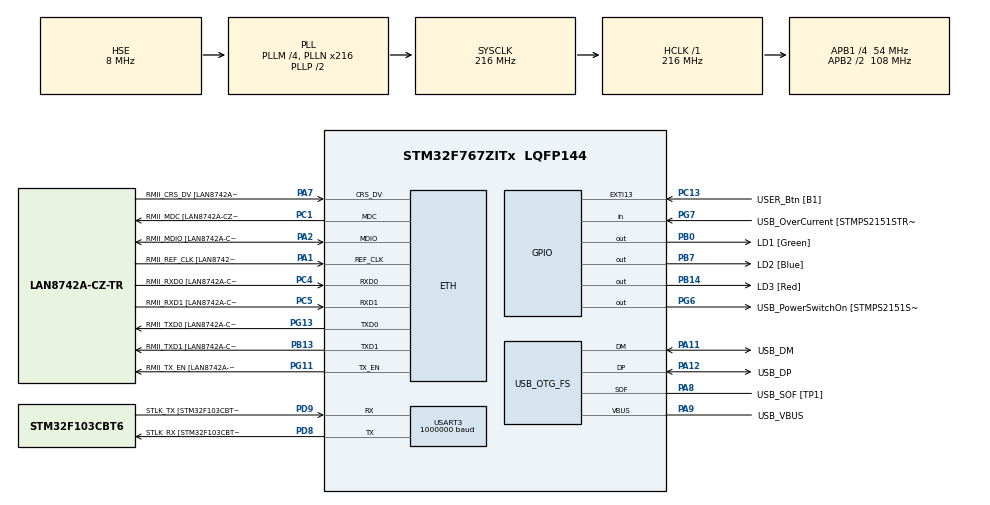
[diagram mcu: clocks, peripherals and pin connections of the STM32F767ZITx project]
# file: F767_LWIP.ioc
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Mcu.Family=STM32F7
NVIC.USART3_IRQn=true\:0\:0\:false\:false\:true\:true\:true
Dma.USART3_RX.0.PeriphInc=DMA_PINC_DISABLE
RCC.CortexFreq_Value=216000000
PG6.Signal=GPIO_Output
Dma.USART3_TX.1.MemInc=DMA_MINC_ENABLE
PB14.GPIO_Label=LD3 [Red]
PG6.GPIO_Label=USB_PowerSwitchOn [STMPS2151STR_EN]
PA14.GPIO_Label=TCK
RCC.SYSCLKSourceVirtual=RCC_SYSCLKSOURCE_PLLCLK
Dma.USART3_TX.1.PeriphDataAlignment=DMA_PDATAALIGN_BYTE
PA11.Mode=Device_Only
PB0.GPIO_Label=LD1 [Green]
PC14/OSC32_IN.Mode=LSE-External-Oscillator
Dma.USART3_TX.1.Instance=DMA1_Stream3
PC5.Mode=RMII
PC13.GPIO_Label=USER_Btn [B1]
PB13.GPIO_Label=RMII_TXD1 [LAN8742A-CZ-TR_TXD1]
PB13.Signal=ETH_TXD1
PG13.Signal=ETH_TXD0
PD9.Mode=Asynchronous
PG11.Signal=ETH_TX_EN
RCC.SYSCLKSource=RCC_SYSCLKSOURCE_PLLCLK
ProjectManager.StackSize=0x1000
USART3.VirtualMode-Asynchronous=VM_ASYNC
PA12.Signal=USB_OTG_FS_DP
USART3.BaudRate=1000000
ETH.PHY_Value=0
PH0/OSC_IN.Mode=HSE-External-Clock-Source
RCC.HCLKFreq_Value=216000000
RCC.APB2TimFreq_Value=216000000
PH1/OSC_OUT.Signal=RCC_OSC_OUT
PD8.Signal=USART3_TX
RCC.AHBFreq_Value=216000000
RCC.HSE_VALUE=8000000
LWIP.LWIP_HAVE_LOOPIF=1
Dma.USART3_RX.0.MemDataAlignment=DMA_MDATAALIGN_BYTE
Dma.USART3_TX.1.Mode=DMA_NORMAL
RCC.PLLMUL=RCC_PLL_MUL9
PC4.GPIO_Label=RMII_RXD0 [LAN8742A-CZ-TR_RXD0]
PA14.Mode=Serial_Wire
PA10.GPIO_Label=USB_ID
Dma.USART3_RX.0.PeriphDataAlignment=DMA_PDATAALIGN_BYTE
PB7.Signal=GPIO_Output
Dma.USART3_RX.0.FIFOMode=DMA_FIFOMODE_DISABLE
PA8.Signal=USB_OTG_FS_SOF
PG13.Mode=RMII
ETH.PHY_Name=LAN8742A_PHY_ADDRESS
TIM4.Period=999
PH1/OSC_OUT.Mode=HSE-External-Clock-Source
Dma.USART3_TX.1.FIFOMode=DMA_FIFOMODE_DISABLE
Dma.USART3_TX.1.Priority=DMA_PRIORITY_MEDIUM
PB7.GPIO_Label=LD2 [Blue]
Dma.USART3_RX.0.Direction=DMA_PERIPH_TO_MEMORY
Mcu.Package=LQFP144
PC14/OSC32_IN.Signal=RCC_OSC32_IN
PA2.GPIO_Label=RMII_MDIO [LAN8742A-CZ-TR_MDIO]
LWIP.LWIP_NETIF_LOOPBACK=0
PA10.Signal=USB_OTG_FS_ID
USB_OTG_FS.VirtualMode=Device_Only
Dma.USART3_RX.0.MemInc=DMA_MINC_ENABLE
RCC.APB2CLKDivider=RCC_HCLK_DIV2
Dma.Request1=USART3_TX
RCC.APB1TimFreq_Value=108000000
PG11.GPIO_Label=RMII_TX_EN [LAN8742A-CZ-TR_TXEN]
PC5.Signal=ETH_RXD1
PB13.Mode=RMII
Dma.USART3_TX.1.PeriphInc=DMA_PINC_DISABLE
Dma.Request0=USART3_RX
PC4.Mode=RMII
PB3.GPIO_Label=SWO
Dma.USART3_RX.0.Instance=DMA1_Stream1
Dma.USART3_TX.1.MemDataAlignment=DMA_MDATAALIGN_BYTE
PA7.Mode=RMII
PG7.Signal=GPIO_Input
PD9.GPIO_Label=STLK_TX [STM32F103CBT6_PA2]
PC13.Signal=GPXTI13
PA9.GPIO_Label=USB_VBUS
PC4.Signal=ETH_RXD0
LWIP.LWIP_IPV6=0
PA11.GPIO_Label=USB_DM
PD9.Signal=USART3_RX
NVIC.DMA1_Stream1_IRQn=true\:0\:0\:false\:false\:true\:false\:true
RCC.APB1CLKDivider=RCC_HCLK_DIV4
PG13.GPIO_Label=RMII_TXD0 [LAN8742A-CZ-TR_TXD0]
ETH.PhyAddress=0
PA12.GPIO_Label=USB_DP
Dma.USART3_RX.0.Mode=DMA_CIRCULAR
VP_LWIP_VS_Enabled.Mode=Enabled
PD8.GPIO_Label=STLK_RX [STM32F103CBT6_PA3]
PA13.Signal=SYS_JTMS-SWDIO
PA9.Mode=Activate_VBUS
PA8.GPIO_Label=USB_SOF [TP1]
LWIP.LWIP_NETIF_EXT_STATUS_CALLBACK=0
ProjectManager.TargetToolchain=MDK-ARM V5.27
LWIP.LWIP_NETIF_LINK_CALLBACK=0
PA9.Signal=USB_OTG_FS_VBUS
RCC.USBFreq_Value=48000000
TIM4.Prescaler=215
PD8.Mode=Asynchronous
PA1.Signal=ETH_REF_CLK
PB14.Signal=GPIO_Output
board=NUCLEO-F767ZI
RCC.VCOOutputFreq_Value=432000000
PH0/OSC_IN.Signal=RCC_OSC_IN
RCC.APB2Freq_Value=108000000
PA1.Mode=RMII
RCC.PRESCALERUSB=RCC_USBCLKSOURCE_PLL_DIV1_5
PG7.GPIO_Label=USB_OverCurrent [STMPS2151STR_FAULT]
PA1.GPIO_Label=RMII_REF_CLK [LAN8742A-CZ-TR_REFCLK0]
PC1.GPIO_Label=RMII_MDC [LAN8742A-CZ-TR_MDC]
PA13.Mode=Serial_Wire
Mcu.Name=STM32F767ZITx
PA2.Signal=ETH_MDIO
PA13.GPIO_Label=TMS
RCC.48MHZClocksFreq_Value=24000000
PB3.Signal=SYS_JTDO-SWO
RCC.SYSCLKFreq_VALUE=216000000
Dma.USART3_RX.0.Priority=DMA_PRIORITY_HIGH
ETH.MediaInterface=ETH_MEDIA_INTERFACE_RMII
PA7.GPIO_Label=RMII_CRS_DV [LAN8742A-CZ-TR_CRS_DV]
LWIP.LWIP_NETIF_STATUS_CALLBACK=0
PA12.Mode=Device_Only
PC5.GPIO_Label=RMII_RXD1 [LAN8742A-CZ-TR_RXD1]
LWIP.IP_FORWARD=0
PC15/OSC32_OUT.Mode=LSE-External-Oscillator
PG11.Mode=RMII
PA11.Signal=USB_OTG_FS_DM
PA14.Signal=SYS_JTCK-SWCLK
ProjectManager.HeapSize=0x1000
LWIP.Version=v2.1.2_Cube
RCC.HSI_VALUE=16000000
PH0/OSC_IN.GPIO_Label=MCO [STM32F103CBT6_PA8]
VP_TIM4_VS_ClockSourceINT.Mode=Internal
RCC.PLLQ=9
NVIC.PriorityGroup=NVIC_PRIORITYGROUP_4
Dma.USART3_TX.1.Direction=DMA_MEMORY_TO_PERIPH
RCC.PLLM=4
RCC.PLLN=216
PA2.Mode=RMII
NVIC.DMA1_Stream3_IRQn=true\:0\:0\:false\:false\:true\:false\:true
PC15/OSC32_OUT.Signal=RCC_OSC32_OUT
PA8.Mode=Activate_SOF_FS
NVIC.TIM4_IRQn=true\:0\:0\:false\:false\:true\:true\:true
RCC.APB1Freq_Value=54000000
PB0.Signal=GPIO_Output
LWIP.LWIP_TCP_SACK_OUT=1
PC1.Signal=ETH_MDC
PC1.Mode=RMII
PA7.Signal=ETH_CRS_DV

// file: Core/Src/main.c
/* USER CODE BEGIN Header */
/**
  ******************************************************************************
  * @file           : main.c
  * @brief          : Main program body
  ******************************************************************************
  * @attention
  *
  * <h2><center>&copy; Copyright (c) 2020 STMicroelectronics.
  * All rights reserved.</center></h2>
  *
  * This software component is licensed by ST under Ultimate Liberty license
  * SLA0044, the "License"; You may not use this file except in compliance with
  * the License. You may obtain a copy of the License at:
  *                             www.st.com/SLA0044
  *
  ******************************************************************************
  */
/* USER CODE END Header */
#include "main.h"
#include "dma.h"
#include "lwip.h"
#include "tim.h"
#include "usart.h"
#include "usb_otg.h"
#include "gpio.h"

/* USER CODE BEGIN Includes */

#include "tcp_client.h"
#include "printf.h"
#include "kfifo.h"
#include "user_task.h"
/* USER CODE END Includes */

void SystemClock_Config(void);

int main(void)
{

  /* MCU Configuration--------------------------------------------------------*/

  /* Reset of all peripherals, Initializes the Flash interface and the Systick. */
  HAL_Init();

  /* Configure the system clock */
  SystemClock_Config();

  /* Initialize all configured peripherals */
  MX_GPIO_Init();
  MX_DMA_Init();
  MX_USART3_UART_Init();
  MX_USB_OTG_FS_PCD_Init();
  MX_LWIP_Init();
  MX_TIM4_Init();
  /* USER CODE BEGIN 2 */
  my_fifo_init(&gFifoRx, gTcpReg.rx_buff, TCP_BUFF_MAX);
  my_fifo_init(&gFifoTx, gTcpReg.tx_buff, TCP_BUFF_MAX);

  HAL_UART_Receive_DMA(&huart3, gTcpReg.dma_buff, UART_DMA_BUFF_MAX);
  __HAL_UART_ENABLE_IT(&huart3, UART_IT_IDLE);

  print_sys_log();
  /* USER CODE END 2 */

  /* Infinite loop */
  /* USER CODE BEGIN WHILE */
  while (1)
  {
	  app_run();

    /* USER CODE END WHILE */

  }
}

void SystemClock_Config(void)
{
  RCC_OscInitTypeDef RCC_OscInitStruct = {0};
  RCC_ClkInitTypeDef RCC_ClkInitStruct = {0};
  RCC_PeriphCLKInitTypeDef PeriphClkInitStruct = {0};

  /** Configure LSE Drive Capability
  */
  HAL_PWR_EnableBkUpAccess();
  /** Configure the main internal regulator output voltage
  */
  __HAL_RCC_PWR_CLK_ENABLE();
  __HAL_PWR_VOLTAGESCALING_CONFIG(PWR_REGULATOR_VOLTAGE_SCALE1);
  /** Initializes the RCC Oscillators according to the specified parameters
  * in the RCC_OscInitTypeDef structure.
  */
  RCC_OscInitStruct.OscillatorType = RCC_OSCILLATORTYPE_HSE;
  RCC_OscInitStruct.HSEState = RCC_HSE_BYPASS;
  RCC_OscInitStruct.PLL.PLLState = RCC_PLL_ON;
  RCC_OscInitStruct.PLL.PLLSource = RCC_PLLSOURCE_HSE;
  RCC_OscInitStruct.PLL.PLLM = 4;
  RCC_OscInitStruct.PLL.PLLN = 216;
  RCC_OscInitStruct.PLL.PLLP = RCC_PLLP_DIV2;
  RCC_OscInitStruct.PLL.PLLQ = 9;
  if (HAL_RCC_OscConfig(&RCC_OscInitStruct) != HAL_OK)
  {
    Error_Handler();
  }
  /** Activate the Over-Drive mode
  */
  if (HAL_PWREx_EnableOverDrive() != HAL_OK)
  {
    Error_Handler();
  }
  /** Initializes the CPU, AHB and APB buses clocks
  */
  RCC_ClkInitStruct.ClockType = RCC_CLOCKTYPE_HCLK|RCC_CLOCKTYPE_SYSCLK
                              |RCC_CLOCKTYPE_PCLK1|RCC_CLOCKTYPE_PCLK2;
  RCC_ClkInitStruct.SYSCLKSource = RCC_SYSCLKSOURCE_PLLCLK;
  RCC_ClkInitStruct.AHBCLKDivider = RCC_SYSCLK_DIV1;
  RCC_ClkInitStruct.APB1CLKDivider = RCC_HCLK_DIV4;
  RCC_ClkInitStruct.APB2CLKDivider = RCC_HCLK_DIV2;

  if (HAL_RCC_ClockConfig(&RCC_ClkInitStruct, FLASH_LATENCY_7) != HAL_OK)
  {
    Error_Handler();
  }
  PeriphClkInitStruct.PeriphClockSelection = RCC_PERIPHCLK_USART3|RCC_PERIPHCLK_CLK48;
  PeriphClkInitStruct.Usart3ClockSelection = RCC_USART3CLKSOURCE_PCLK1;
  PeriphClkInitStruct.Clk48ClockSelection = RCC_CLK48SOURCE_PLL;
  if (HAL_RCCEx_PeriphCLKConfig(&PeriphClkInitStruct) != HAL_OK)
  {
    Error_Handler();
  }
}

void Error_Handler(void)
{
}

/************************ (C) COPYRIGHT STMicroelectronics *****END OF FILE****/
